# PY32F003xx register map
Vendor: Puya; Series: PY32F0; File version: 1.0.0
CPU: CM0+ r0p1, little endian, no MPU, no FPU, 4 interrupt priority bits
Registers are 32-bit, read-write, reset 0x0 unless marked. A register's access mark holds for its fields unless they carry their own. Offsets are from the block's base; [hi:lo] are bit positions; {n}, {i} and the like mark numbered series.

## TIM3 — General purpose timer
Base 0x40000400
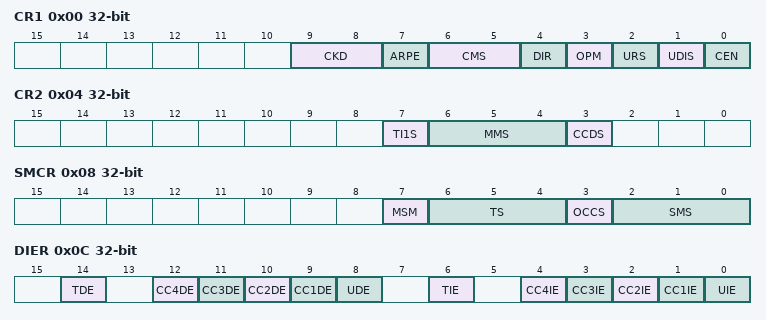
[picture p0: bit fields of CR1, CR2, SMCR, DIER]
0x00 CR1 — control register 1
  [9:8] CKD — Clock division
    1=0; 2=1
  [7] ARPE — Auto-reload preload enable
  [6:5] CMS — Center-aligned modeselection
    1=0; 2=1
  [4] DIR — Direction
  [3] OPM — One-pulse mode
  [2] URS — Update request source
  [1] UDIS — Update disable
  [0] CEN — Counter enable
0x04 CR2 — control register 2
  [7] TI1S — TI1 selection
  [6:4] MMS — Master mode selection
    1=0; 2=1; 4=2
  [3] CCDS — Capture/compare DMAselection
0x08 SMCR — slave mode control register
  [7] MSM — Master/Slave mode
  [6:4] TS — Trigger selection
    1=0; 2=1; 4=2
  [3] OCCS — OCREF Clear Selection
  [2:0] SMS — Slave mode selection
    1=0; 2=1; 4=2
0x0C DIER — DMA/Interrupt enable register
  [14] TDE — Trigger DMA request enable
  [n+8] CC{n}DE (n=1..4) — Capture/Compare {n} DMA requestenable
  [8] UDE — Update DMA request enable
  [6] TIE — Trigger interrupt enable
  [n] CC{n}IE (n=1..4) — Capture/Compare {n} interruptenable
  [0] UIE — Update interrupt enable
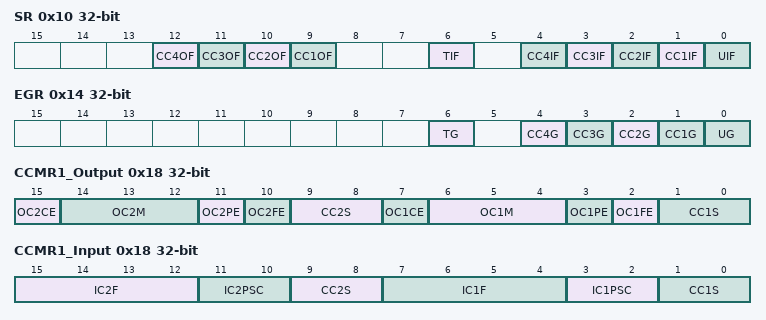
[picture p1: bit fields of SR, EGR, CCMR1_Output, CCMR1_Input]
0x10 SR — status register
  [12] CC4OF — Capture/Compare 4 overcaptureflag
  [11] CC3OF — Capture/Compare 3 overcaptureflag
  [10] CC2OF — Capture/compare 2 overcaptureflag
  [9] CC1OF — Capture/Compare 1 overcaptureflag
  [6] TIF — Trigger interrupt flag
  [4] CC4IF — Capture/Compare 4 interruptflag
  [3] CC3IF — Capture/Compare 3 interruptflag
  [2] CC2IF — Capture/Compare 2 interruptflag
  [1] CC1IF — Capture/compare 1 interruptflag
  [0] UIF — Update interrupt flag
0x14 EGR wo — event generation register
  [6] TG — Trigger generation
  [n] CC{n}G (n=1..4) — Capture/compare {n}generation
  [0] UG — Update generation
0x18 CCMR1_Output — capture/compare mode register 1 (outputmode)
  [15] OC2CE — Output compare 2 clearenable
  [14:12] OC2M — Output compare 2 mode
  [11] OC2PE — Output compare 2 preloadenable
  [10] OC2FE — Output compare 2 fastenable
  [9:8] CC2S — Capture/Compare 2selection
  [7] OC1CE — Output compare 1 clearenable
  [6:4] OC1M — Output compare 1 mode
  [3] OC1PE — Output compare 1 preloadenable
  [2] OC1FE — Output compare 1 fastenable
  [1:0] CC1S — Capture/Compare 1selection
0x18 CCMR1_Input (alternate view of CCMR1_Output) — capture/compare mode register 1 (inputmode)
  [15:12] IC2F — Input capture 2 filter
  [11:10] IC2PSC — Input capture 2 prescaler
  [9:8] CC2S — Capture/compare 2selection
  [7:4] IC1F — Input capture 1 filter
  [3:2] IC1PSC — Input capture 1 prescaler
  [1:0] CC1S — Capture/Compare 1selection
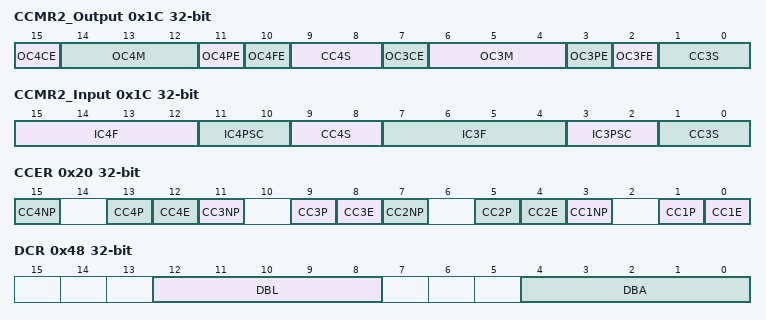
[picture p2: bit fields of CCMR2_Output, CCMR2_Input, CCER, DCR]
0x1C CCMR2_Output — capture/compare mode register 2 (outputmode)
  [15] OC4CE — Output compare 4 clearenable
  [14:12] OC4M — Output compare 4 mode
  [11] OC4PE — Output compare 4 preloadenable
  [10] OC4FE — Output compare 4 fastenable
  [9:8] CC4S — Capture/Compare 4selection
  [7] OC3CE — Output compare 3 clearenable
  [6:4] OC3M — Output compare 3 mode
  [3] OC3PE — Output compare 3 preloadenable
  [2] OC3FE — Output compare 3 fastenable
  [1:0] CC3S — Capture/Compare 3selection
0x1C CCMR2_Input (alternate view of CCMR2_Output) — capture/compare mode register 2 (inputmode)
  [15:12] IC4F — Input capture 4 filter
  [11:10] IC4PSC — Input capture 4 prescaler
  [9:8] CC4S — Capture/Compare 4selection
  [7:4] IC3F — Input capture 3 filter
  [3:2] IC3PSC — Input capture 3 prescaler
  [1:0] CC3S — Capture/Compare 3selection
0x20 CCER — capture/compare enableregister
  [4n-1] CC{n}NP (n=1..4) — Capture/Compare {n} outputPolarity
  [4n-3] CC{n}P (n=1..4) — Capture/Compare {n} outputPolarity
  [4n-4] CC{n}E (n=1..4) — Capture/Compare {n} outputenable
0x24 CNT — counter
  [15:0] CNT — counter value
0x28 PSC — prescaler
  [15:0] PSC — Prescaler value
0x2C ARR — auto-reload register
  [15:0] ARR — Auto-reload value
0x34 CCR1 — capture/compare register 1
  [15:0] CCR1 — Capture/Compare 1 value
0x38 CCR2 — capture/compare register 2
  [15:0] CCR2 — Capture/Compare 2 value
0x3C CCR3 — capture/compare register 3
  [15:0] CCR3 — Capture/Compare value
0x40 CCR4 — capture/compare register 4
  [15:0] CCR4 — Capture/Compare value
0x48 DCR — DMA control register
  [12:8] DBL — DMA burst length
    1=0; 2=1; 4=2; 8=3; 16=4
  [4:0] DBA — DMA base address
    1=0; 2=1; 4=2; 8=3; 16=4
0x4C DMAR — DMA address for full transfer
  [31:0] DMAB — DMA register for burstaccesses
